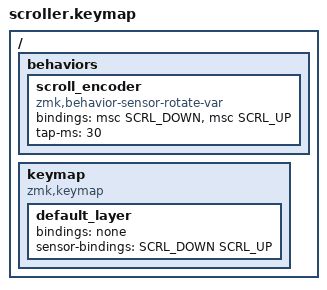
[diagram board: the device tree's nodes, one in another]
#include <behaviors.dtsi>
#include <dt-bindings/zmk/bt.h>
#include <dt-bindings/zmk/keys.h>
#include <dt-bindings/zmk/mouse.h>
#include <dt-bindings/zmk/outputs.h>

/ {
    behaviors {
        scroll_encoder: scroll_encoder {
        compatible = "zmk,behavior-sensor-rotate-var";
        #sensor-binding-cells = <0>;
        bindings = <&msc SCRL_DOWN>, <&msc SCRL_UP>;
        tap-ms = <30>;
        };

//        mouse_scroll: behavior_mouse_scroll {
//            compatible = "zmk,behavior-sensor-rotate";
//            #sensor-binding-cells = <2>;
//        };
    };

    keymap {
        compatible = "zmk,keymap";

        default_layer {
            bindings = < &none >;
            sensor-bindings = < SCRL_DOWN SCRL_UP >;
        };
    };
};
